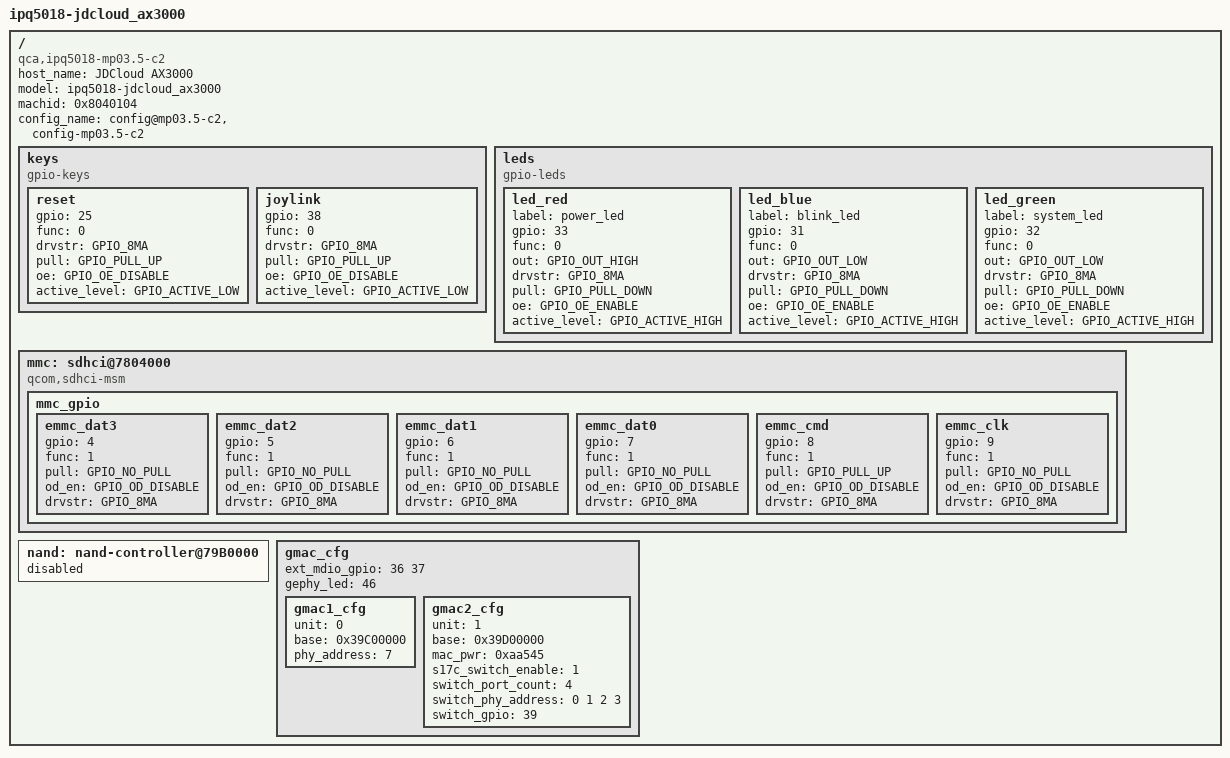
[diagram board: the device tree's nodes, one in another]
/*
 * Copyright (c) 2016-2020, The Linux Foundation. All rights reserved.
 *
 * This program is free software; you can redistribute it and/or modify
 * it under the terms of the GNU General Public License version 2 and
 * only version 2 as published by the Free Software Foundation.
 *
 * This program is distributed in the hope that it will be useful,
 * but WITHOUT ANY WARRANTY; without even the implied warranty of
 * MERCHANTABILITY or FITNESS FOR A PARTICULAR PURPOSE.  See the
 * GNU General Public License for more details.
 */
#include "ipq5018-mp03.5-c1.dts"
/ {
	host_name = "JDCloud AX3000";
	model ="ipq5018-jdcloud_ax3000";
	compatible = "qca,ipq5018-mp03.5-c2", "qca,ipq5018";
	machid = <0x8040104>;
	config_name = "config@mp03.5-c2", "config-mp03.5-c2";

    keys {
		compatible = "gpio-keys";

        reset {
            gpio = <25>;
            func = <0>;
            drvstr = <GPIO_8MA>;
            pull = <GPIO_PULL_UP>;
            oe = <GPIO_OE_DISABLE>;
			active_level = <GPIO_ACTIVE_LOW>;
        };

        joylink {
            gpio = <38>;
            func = <0>;
            drvstr = <GPIO_8MA>;
            pull = <GPIO_PULL_UP>;
            oe = <GPIO_OE_DISABLE>;
			active_level = <GPIO_ACTIVE_LOW>;
        };
    };

    leds {
		compatible = "gpio-leds";

        led_red {
			label = "power_led";
            gpio = <33>;
            func = <0>;
            out = <GPIO_OUT_HIGH>;
            drvstr = <GPIO_8MA>;
            pull = <GPIO_PULL_DOWN>;
            oe = <GPIO_OE_ENABLE>;
            active_level = <GPIO_ACTIVE_HIGH>;
        };

        led_blue {
			label = "blink_led";
            gpio = <31>;
            func = <0>;
            out = <GPIO_OUT_LOW>;
            drvstr = <GPIO_8MA>;
            pull = <GPIO_PULL_DOWN>;
            oe = <GPIO_OE_ENABLE>;
            active_level = <GPIO_ACTIVE_HIGH>;
        };

        led_green {
			label = "system_led";
            gpio = <32>;
            func = <0>;
            out = <GPIO_OUT_LOW>;
            drvstr = <GPIO_8MA>;
            pull = <GPIO_PULL_DOWN>;
            oe = <GPIO_OE_ENABLE>;
            active_level = <GPIO_ACTIVE_HIGH>;
        };
    };

	mmc: sdhci@7804000 {
		compatible = "qcom,sdhci-msm";
		status = "okay";
		mmc_gpio {
			emmc_dat3 {
				gpio = <4>;
				func = <1>;
				pull = <GPIO_NO_PULL>;
				od_en = <GPIO_OD_DISABLE>;
				drvstr = <GPIO_8MA>;
			};
			emmc_dat2 {
				gpio = <5>;
				func = <1>;
				pull = <GPIO_NO_PULL>;
				od_en = <GPIO_OD_DISABLE>;
				drvstr = <GPIO_8MA>;
			};
			emmc_dat1 {
				gpio = <6>;
				func = <1>;
				pull = <GPIO_NO_PULL>;
				od_en = <GPIO_OD_DISABLE>;
				drvstr = <GPIO_8MA>;
			};
			emmc_dat0 {
				gpio = <7>;
				func = <1>;
				pull = <GPIO_NO_PULL>;
				od_en = <GPIO_OD_DISABLE>;
				drvstr = <GPIO_8MA>;
			};
			emmc_cmd{
				gpio = <8>;
				func = <1>;
				pull = <GPIO_PULL_UP>;
				od_en = <GPIO_OD_DISABLE>;
				drvstr = <GPIO_8MA>;
			};
			emmc_clk{
				gpio = <9>;
				func = <1>;
				pull = <GPIO_NO_PULL>;
				od_en = <GPIO_OD_DISABLE>;
				drvstr = <GPIO_8MA>;
			};
		};
	};

	nand: nand-controller@79B0000 {
		status = "disabled";
	};

	gmac_cfg {
		ext_mdio_gpio = <36 37>;
		gephy_led = <46>;

		gmac1_cfg {
			unit = <0>;
			base = <0x39C00000>;
			phy_address = <7>;
		};

		gmac2_cfg {
			unit = <1>;
			base = <0x39D00000>;
			mac_pwr = <0xaa545>;
			s17c_switch_enable = <1>;
			switch_port_count = <4>;
			switch_phy_address = <0 1 2 3>;
			switch_gpio = <39>;
			/delete-property/phy_address;
			/delete-property/napa_gpio;
		};
	};
};
